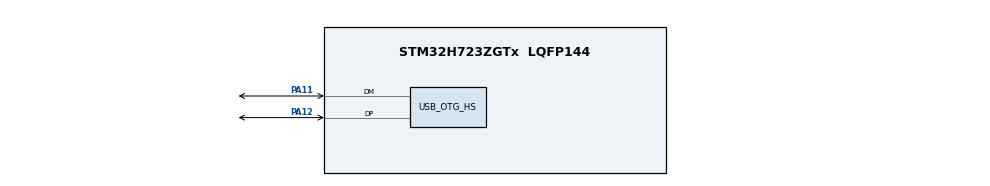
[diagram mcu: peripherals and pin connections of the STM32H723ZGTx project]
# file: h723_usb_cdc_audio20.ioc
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Mcu.Family=STM32H7
Mcu.Name=STM32H723ZGTx
Mcu.Package=LQFP144
NVIC.OTG_HS_IRQn=true\:0\:0\:false\:false\:true\:false\:true\:true
NVIC.PriorityGroup=NVIC_PRIORITYGROUP_4
PA11.Mode=Device_Only_FS
PA11.Signal=USB_OTG_HS_DM
PA12.Mode=Device_Only_FS
PA12.Signal=USB_OTG_HS_DP
ProjectManager.HeapSize=0x2000
ProjectManager.StackSize=0x400
ProjectManager.TargetToolchain=STM32CubeIDE
RCC.ADCFreq_Value=129000000
RCC.APB1Freq_Value=137500000
RCC.APB2Freq_Value=137500000
RCC.APB3Freq_Value=137500000
RCC.APB4Freq_Value=137500000
RCC.CortexFreq_Value=550000000
RCC.D1PPRE=RCC_APB3_DIV2
RCC.D2PPRE1=RCC_APB1_DIV2
RCC.D2PPRE2=RCC_APB2_DIV2
RCC.D3PPRE=RCC_APB4_DIV2
RCC.DIVM1=4
RCC.DIVN1=34
RCC.DIVP1=1
RCC.HCLKFreq_Value=275000000
RCC.HPRE=RCC_HCLK_DIV2
RCC.HSE_VALUE=25000000
RCC.PLL2FRACN=0
RCC.PLL3FRACN=0
RCC.PLLFRACN=3072
RCC.SYSCLKFreq_VALUE=550000000
RCC.SYSCLKSource=RCC_SYSCLKSOURCE_PLLCLK
RCC.USBCLockSelection=RCC_USBCLKSOURCE_HSI48
RCC.USBFreq_Value=48000000
USB_DEVICE.CLASS_NAME_HS=AUDIO
USB_DEVICE.VirtualMode=Audio
USB_DEVICE.VirtualModeHS=Audio_HS
USB_OTG_HS.VirtualMode-Device_Only_FS=Device_Only_FS
VP_RCC_USB.Mode=USB_HS
VP_USB_DEVICE_VS_USB_DEVICE_AUDIO_HS.Mode=AUDIO_HS
board=custom

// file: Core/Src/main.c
/* USER CODE BEGIN Header */
/**
  ******************************************************************************
  * @file           : main.c
  * @brief          : Main program body
  ******************************************************************************
  * @attention
  *
  * Copyright (c) 2023 STMicroelectronics.
  * All rights reserved.
  *
  * This software is licensed under terms that can be found in the LICENSE file
  * in the root directory of this software component.
  * If no LICENSE file comes with this software, it is provided AS-IS.
  *
  ******************************************************************************
  */
/* USER CODE END Header */
#include "main.h"
#include "usb_device.h"

/* USER CODE BEGIN PV */
uint16_t bufferIn[192]={0};
uint32_t bufferLen=0;
uint16_t valueIn=0;
/* USER CODE END PV */

void SystemClock_Config(void);
static void MX_GPIO_Init(void);

/* USER CODE BEGIN 0 */

/**
  * @brief  This function is executed in case of an error occurrence in Audio Class.
  * @param  None
  * @retval None
  */
void USBD_error_handler(void)
{
Error_Handler();
}
/* USER CODE END 0 */

int main(void)
{

  /* MCU Configuration--------------------------------------------------------*/

  /* Reset of all peripherals, Initializes the Flash interface and the Systick. */
  HAL_Init();

  /* Configure the system clock */
  SystemClock_Config();

  /* Initialize all configured peripherals */
  MX_GPIO_Init();
  MX_USB_DEVICE_Init();

  /* Infinite loop */
  /* USER CODE BEGIN WHILE */
  while (1)
  {
    bufferLen=AUDIO_GetPacketLength();//check if we have space in buffer
    if(bufferLen>0){
      bufferIn[0]=valueIn;//marks in buffer to check them in usb analyzer
      bufferIn[95]=valueIn+1;
      bufferIn[96]=valueIn+2;
      bufferIn[191]=valueIn+3;
      AUDIO_SendINData(bufferIn,bufferLen*2);//send new data if buffer have space
      valueIn++;
    }

    AUDIO_GetSpeakerData();
    /* USER CODE END WHILE */

  }
}

void SystemClock_Config(void)
{
  RCC_OscInitTypeDef RCC_OscInitStruct = {0};
  RCC_ClkInitTypeDef RCC_ClkInitStruct = {0};
  RCC_CRSInitTypeDef RCC_CRSInitStruct = {0};

  /** Supply configuration update enable
  */
  HAL_PWREx_ConfigSupply(PWR_LDO_SUPPLY);

  /** Configure the main internal regulator output voltage
  */
  __HAL_PWR_VOLTAGESCALING_CONFIG(PWR_REGULATOR_VOLTAGE_SCALE0);

  while(!__HAL_PWR_GET_FLAG(PWR_FLAG_VOSRDY)) {}

  /** Initializes the RCC Oscillators according to the specified parameters
  * in the RCC_OscInitTypeDef structure.
  */
  RCC_OscInitStruct.OscillatorType = RCC_OSCILLATORTYPE_HSI48|RCC_OSCILLATORTYPE_HSI;
  RCC_OscInitStruct.HSIState = RCC_HSI_DIV1;
  RCC_OscInitStruct.HSICalibrationValue = 64;
  RCC_OscInitStruct.HSI48State = RCC_HSI48_ON;
  RCC_OscInitStruct.PLL.PLLState = RCC_PLL_ON;
  RCC_OscInitStruct.PLL.PLLSource = RCC_PLLSOURCE_HSI;
  RCC_OscInitStruct.PLL.PLLM = 4;
  RCC_OscInitStruct.PLL.PLLN = 34;
  RCC_OscInitStruct.PLL.PLLP = 1;
  RCC_OscInitStruct.PLL.PLLQ = 2;
  RCC_OscInitStruct.PLL.PLLR = 2;
  RCC_OscInitStruct.PLL.PLLRGE = RCC_PLL1VCIRANGE_3;
  RCC_OscInitStruct.PLL.PLLVCOSEL = RCC_PLL1VCOWIDE;
  RCC_OscInitStruct.PLL.PLLFRACN = 3072;
  if (HAL_RCC_OscConfig(&RCC_OscInitStruct) != HAL_OK)
  {
    Error_Handler();
  }

  /** Initializes the CPU, AHB and APB buses clocks
  */
  RCC_ClkInitStruct.ClockType = RCC_CLOCKTYPE_HCLK|RCC_CLOCKTYPE_SYSCLK
                              |RCC_CLOCKTYPE_PCLK1|RCC_CLOCKTYPE_PCLK2
                              |RCC_CLOCKTYPE_D3PCLK1|RCC_CLOCKTYPE_D1PCLK1;
  RCC_ClkInitStruct.SYSCLKSource = RCC_SYSCLKSOURCE_PLLCLK;
  RCC_ClkInitStruct.SYSCLKDivider = RCC_SYSCLK_DIV1;
  RCC_ClkInitStruct.AHBCLKDivider = RCC_HCLK_DIV2;
  RCC_ClkInitStruct.APB3CLKDivider = RCC_APB3_DIV2;
  RCC_ClkInitStruct.APB1CLKDivider = RCC_APB1_DIV2;
  RCC_ClkInitStruct.APB2CLKDivider = RCC_APB2_DIV2;
  RCC_ClkInitStruct.APB4CLKDivider = RCC_APB4_DIV2;

  if (HAL_RCC_ClockConfig(&RCC_ClkInitStruct, FLASH_LATENCY_3) != HAL_OK)
  {
    Error_Handler();
  }

  /** Enable the SYSCFG APB clock
  */
  __HAL_RCC_CRS_CLK_ENABLE();

  /** Configures CRS
  */
  RCC_CRSInitStruct.Prescaler = RCC_CRS_SYNC_DIV1;
  RCC_CRSInitStruct.Source = RCC_CRS_SYNC_SOURCE_USB2;
  RCC_CRSInitStruct.Polarity = RCC_CRS_SYNC_POLARITY_RISING;
  RCC_CRSInitStruct.ReloadValue = __HAL_RCC_CRS_RELOADVALUE_CALCULATE(48000000,1000);
  RCC_CRSInitStruct.ErrorLimitValue = 34;
  RCC_CRSInitStruct.HSI48CalibrationValue = 32;

  HAL_RCCEx_CRSConfig(&RCC_CRSInitStruct);
}

static void MX_GPIO_Init(void)
{

  /* GPIO Ports Clock Enable */
  __HAL_RCC_GPIOA_CLK_ENABLE();

}

void Error_Handler(void)
{
  __disable_irq();
  while (1)
  {
  }
}
